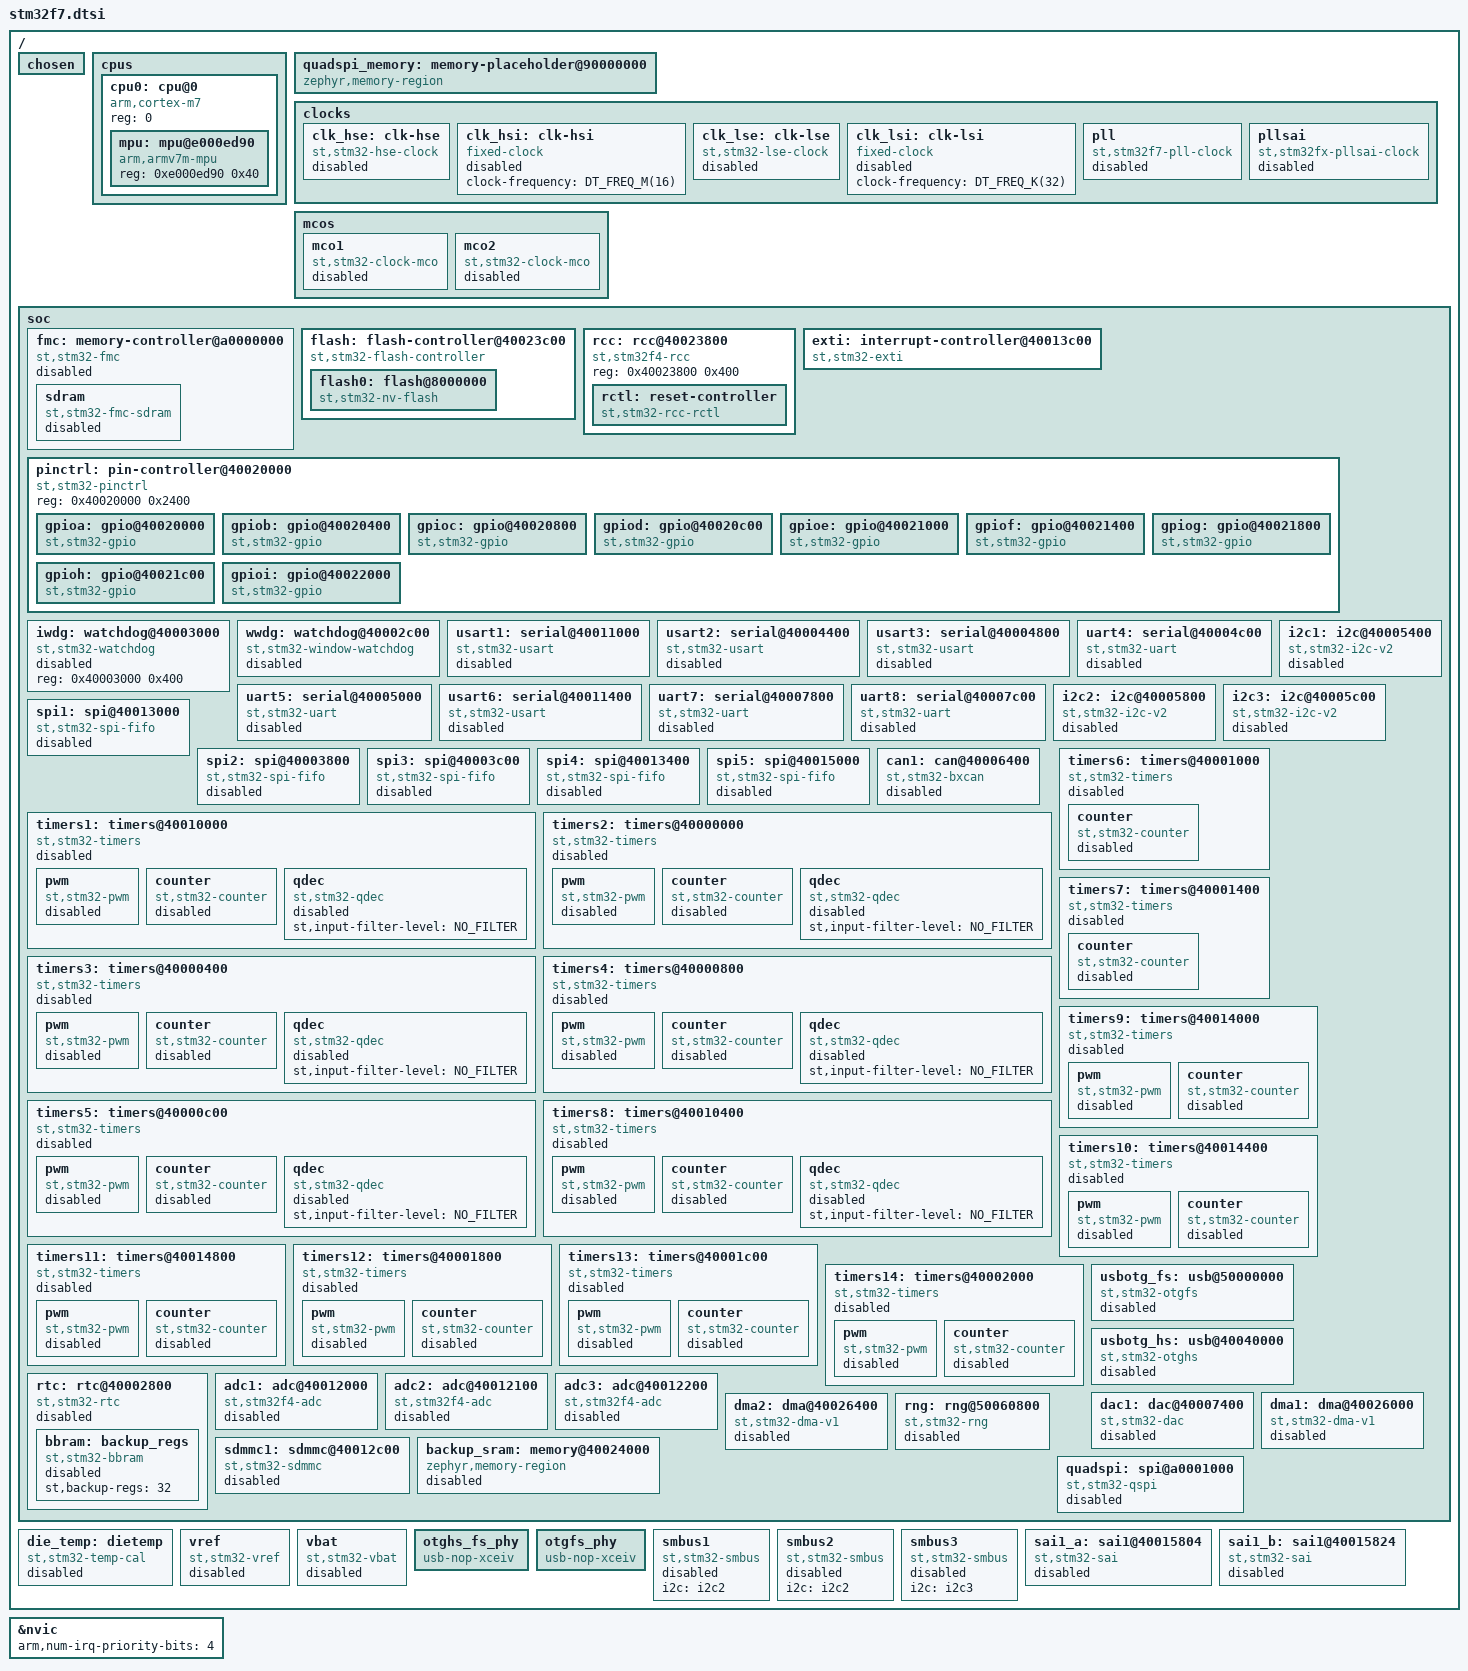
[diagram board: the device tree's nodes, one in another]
/*
 * Copyright (c) 2018 Yurii Hamann
 * Copyright (c) 2019 Centaur Analytics, Inc
 * Copyright (c) 2024 STMicroelectronics
 * Copyright (c) 2025 Mario Paja
 *
 * SPDX-License-Identifier: Apache-2.0
 */

#include <arm/armv7-m.dtsi>
#include <zephyr/dt-bindings/clock/stm32f7_clock.h>
#include <zephyr/dt-bindings/i2c/i2c.h>
#include <zephyr/dt-bindings/gpio/gpio.h>
#include <zephyr/dt-bindings/pwm/pwm.h>
#include <zephyr/dt-bindings/pwm/stm32_pwm.h>
#include <zephyr/dt-bindings/dma/stm32_dma.h>
#include <zephyr/dt-bindings/adc/stm32f4_adc.h>
#include <zephyr/dt-bindings/reset/stm32f2_4_7_reset.h>
#include <zephyr/dt-bindings/adc/adc.h>
#include <zephyr/dt-bindings/memory-controller/stm32-fmc-sdram.h>
#include <zephyr/dt-bindings/sensor/qdec_stm32.h>
#include <zephyr/dt-bindings/memory-attr/memory-attr.h>
#include <zephyr/dt-bindings/memory-attr/memory-attr-arm.h>
#include <freq.h>
#include <mem.h>

/ {
	chosen {
		zephyr,entropy = &rng;
		zephyr,flash-controller = &flash;
	};

	cpus {
		#address-cells = <1>;
		#size-cells = <0>;

		cpu0: cpu@0 {
			device_type = "cpu";
			compatible = "arm,cortex-m7";
			reg = <0>;
			#address-cells = <1>;
			#size-cells = <1>;

			mpu: mpu@e000ed90 {
				compatible = "arm,armv7m-mpu";
				reg = <0xe000ed90 0x40>;
			};
		};
	};

	quadspi_memory: memory-placeholder@90000000 {
		compatible = "zephyr,memory-region", "mmio-sram";
		reg = <0x90000000 DT_SIZE_M(256)>;
		zephyr,memory-region = "QSPI_PLACEHOLDER";
		zephyr,memory-attr = <DT_MEM_ARM(ATTR_MPU_EXTMEM)>;
	};

	clocks {
		clk_hse: clk-hse {
			#clock-cells = <0>;
			compatible = "st,stm32-hse-clock";
			status = "disabled";
		};

		clk_hsi: clk-hsi {
			#clock-cells = <0>;
			compatible = "fixed-clock";
			clock-frequency = <DT_FREQ_M(16)>;
			status = "disabled";
		};

		clk_lse: clk-lse {
			#clock-cells = <0>;
			compatible = "st,stm32-lse-clock";
			clock-frequency = <32768>;
			driving-capability = <0>;
			status = "disabled";
		};

		clk_lsi: clk-lsi {
			#clock-cells = <0>;
			compatible = "fixed-clock";
			clock-frequency = <DT_FREQ_K(32)>;
			status = "disabled";
		};

		pll: pll {
			#clock-cells = <0>;
			compatible = "st,stm32f7-pll-clock";
			status = "disabled";
		};

		pllsai: pllsai {
			compatible = "st,stm32fx-pllsai-clock";
			#clock-cells = <0>;
			status = "disabled";
		};
	};

	mcos {
		mco1: mco1 {
			compatible = "st,stm32-clock-mco";
			status = "disabled";
		};

		mco2: mco2 {
			compatible = "st,stm32-clock-mco";
			status = "disabled";
		};
	};

	soc {
		fmc: memory-controller@a0000000 {
			compatible = "st,stm32-fmc";
			reg = <0xa0000000 0x400>;
			clocks = <&rcc STM32_CLOCK(AHB3, 0)>;
			status = "disabled";

			sdram: sdram {
				compatible = "st,stm32-fmc-sdram";
				#address-cells = <1>;
				#size-cells = <0>;
				status = "disabled";
			};
		};

		flash: flash-controller@40023c00 {
			compatible = "st,stm32-flash-controller", "st,stm32f7-flash-controller";
			reg = <0x40023c00 0x400>;
			interrupts = <4 0>;

			#address-cells = <1>;
			#size-cells = <1>;

			flash0: flash@8000000 {
				compatible = "st,stm32-nv-flash", "soc-nv-flash";

				write-block-size = <1>;
				/* maximum erase time (ms) for a 256K sector */
				max-erase-time = <4000>;
			};
		};

		rcc: rcc@40023800 {
			compatible = "st,stm32f4-rcc";
			#clock-cells = <2>;
			reg = <0x40023800 0x400>;

			rctl: reset-controller {
				compatible = "st,stm32-rcc-rctl";
				#reset-cells = <1>;
			};
		};

		exti: interrupt-controller@40013c00 {
			compatible = "st,stm32-exti";
			interrupt-controller;
			#interrupt-cells = <1>;
			#address-cells = <0>;
			reg = <0x40013c00 0x400>;
			clocks = <&rcc STM32_CLOCK(APB2, 14)>;
			num-lines = <32>;
			interrupts = <6 0>, <7 0>, <8 0>, <9 0>,
				     <10 0>, <23 0>, <40 0>;
			interrupt-names = "line0", "line1", "line2", "line3",
					  "line4", "line5-9", "line10-15";
			line-ranges = <0 1>, <1 1>, <2 1>, <3 1>,
				      <4 1>, <5 5>, <10 6>;
		};

		pinctrl: pin-controller@40020000 {
			compatible = "st,stm32-pinctrl";
			#address-cells = <1>;
			#size-cells = <1>;
			reg = <0x40020000 0x2400>;

			gpioa: gpio@40020000 {
				compatible = "st,stm32-gpio";
				gpio-controller;
				#gpio-cells = <2>;
				reg = <0x40020000 0x400>;
				clocks = <&rcc STM32_CLOCK(AHB1, 0)>;
			};

			gpiob: gpio@40020400 {
				compatible = "st,stm32-gpio";
				gpio-controller;
				#gpio-cells = <2>;
				reg = <0x40020400 0x400>;
				clocks = <&rcc STM32_CLOCK(AHB1, 1)>;
			};

			gpioc: gpio@40020800 {
				compatible = "st,stm32-gpio";
				gpio-controller;
				#gpio-cells = <2>;
				reg = <0x40020800 0x400>;
				clocks = <&rcc STM32_CLOCK(AHB1, 2)>;
			};

			gpiod: gpio@40020c00 {
				compatible = "st,stm32-gpio";
				gpio-controller;
				#gpio-cells = <2>;
				reg = <0x40020c00 0x400>;
				clocks = <&rcc STM32_CLOCK(AHB1, 3)>;
			};

			gpioe: gpio@40021000 {
				compatible = "st,stm32-gpio";
				gpio-controller;
				#gpio-cells = <2>;
				reg = <0x40021000 0x400>;
				clocks = <&rcc STM32_CLOCK(AHB1, 4)>;
			};

			gpiof: gpio@40021400 {
				compatible = "st,stm32-gpio";
				gpio-controller;
				#gpio-cells = <2>;
				reg = <0x40021400 0x400>;
				clocks = <&rcc STM32_CLOCK(AHB1, 5)>;
			};

			gpiog: gpio@40021800 {
				compatible = "st,stm32-gpio";
				gpio-controller;
				#gpio-cells = <2>;
				reg = <0x40021800 0x400>;
				clocks = <&rcc STM32_CLOCK(AHB1, 6)>;
			};

			gpioh: gpio@40021c00 {
				compatible = "st,stm32-gpio";
				gpio-controller;
				#gpio-cells = <2>;
				reg = <0x40021c00 0x400>;
				clocks = <&rcc STM32_CLOCK(AHB1, 7)>;
			};

			gpioi: gpio@40022000 {
				compatible = "st,stm32-gpio";
				gpio-controller;
				#gpio-cells = <2>;
				reg = <0x40022000 0x400>;
				clocks = <&rcc STM32_CLOCK(AHB1, 8)>;
			};
		};

		iwdg: watchdog@40003000 {
			compatible = "st,stm32-watchdog";
			reg = <0x40003000 0x400>;
			status = "disabled";
		};

		wwdg: watchdog@40002c00 {
			compatible = "st,stm32-window-watchdog";
			reg = <0x40002c00 0x400>;
			clocks = <&rcc STM32_CLOCK(APB1, 11)>;
			interrupts = <0 7>;
			status = "disabled";
		};

		usart1: serial@40011000 {
			compatible = "st,stm32-usart", "st,stm32-uart";
			reg = <0x40011000 0x400>;
			clocks = <&rcc STM32_CLOCK(APB2, 4)>;
			resets = <&rctl STM32_RESET(APB2, 4)>;
			interrupts = <37 0>;
			status = "disabled";
		};

		usart2: serial@40004400 {
			compatible = "st,stm32-usart", "st,stm32-uart";
			reg = <0x40004400 0x400>;
			clocks = <&rcc STM32_CLOCK(APB1, 17)>;
			resets = <&rctl STM32_RESET(APB1, 17)>;
			interrupts = <38 0>;
			status = "disabled";
		};

		usart3: serial@40004800 {
			compatible = "st,stm32-usart", "st,stm32-uart";
			reg = <0x40004800 0x400>;
			clocks = <&rcc STM32_CLOCK(APB1, 18)>;
			resets = <&rctl STM32_RESET(APB1, 18)>;
			interrupts = <39 0>;
			status = "disabled";
		};

		uart4: serial@40004c00 {
			compatible = "st,stm32-uart";
			reg = <0x40004c00 0x400>;
			clocks = <&rcc STM32_CLOCK(APB1, 19)>;
			resets = <&rctl STM32_RESET(APB1, 19)>;
			interrupts = <52 0>;
			status = "disabled";
		};

		uart5: serial@40005000 {
			compatible = "st,stm32-uart";
			reg = <0x40005000 0x400>;
			clocks = <&rcc STM32_CLOCK(APB1, 20)>;
			resets = <&rctl STM32_RESET(APB1, 20)>;
			interrupts = <53 0>;
			status = "disabled";
		};

		usart6: serial@40011400 {
			compatible = "st,stm32-usart", "st,stm32-uart";
			reg = <0x40011400 0x400>;
			clocks = <&rcc STM32_CLOCK(APB2, 5)>;
			resets = <&rctl STM32_RESET(APB2, 5)>;
			interrupts = <71 0>;
			status = "disabled";
		};

		uart7: serial@40007800 {
			compatible = "st,stm32-uart";
			reg = <0x40007800 0x400>;
			clocks = <&rcc STM32_CLOCK(APB1, 30)>;
			resets = <&rctl STM32_RESET(APB1, 30)>;
			interrupts = <82 0>;
			status = "disabled";
		};

		uart8: serial@40007c00 {
			compatible = "st,stm32-uart";
			reg = <0x40007c00 0x400>;
			clocks = <&rcc STM32_CLOCK(APB1, 31)>;
			resets = <&rctl STM32_RESET(APB1, 31)>;
			interrupts = <83 0>;
			status = "disabled";
		};

		i2c1: i2c@40005400 {
			compatible = "st,stm32-i2c-v2";
			clock-frequency = <I2C_BITRATE_STANDARD>;
			#address-cells = <1>;
			#size-cells = <0>;
			reg = <0x40005400 0x400>;
			clocks = <&rcc STM32_CLOCK(APB1, 21)>;
			interrupts = <31 0>, <32 0>;
			interrupt-names = "event", "error";
			status = "disabled";
		};

		i2c2: i2c@40005800 {
			compatible = "st,stm32-i2c-v2";
			clock-frequency = <I2C_BITRATE_STANDARD>;
			#address-cells = <1>;
			#size-cells = <0>;
			reg = <0x40005800 0x400>;
			clocks = <&rcc STM32_CLOCK(APB1, 22)>;
			interrupts = <33 0>, <34 0>;
			interrupt-names = "event", "error";
			status = "disabled";
		};

		i2c3: i2c@40005c00 {
			compatible = "st,stm32-i2c-v2";
			clock-frequency = <I2C_BITRATE_STANDARD>;
			#address-cells = <1>;
			#size-cells = <0>;
			reg = <0x40005c00 0x400>;
			clocks = <&rcc STM32_CLOCK(APB1, 23)>;
			interrupts = <72 0>, <73 0>;
			interrupt-names = "event", "error";
			status = "disabled";
		};

		spi1: spi@40013000 {
			compatible = "st,stm32-spi-fifo", "st,stm32-spi";
			#address-cells = <1>;
			#size-cells = <0>;
			reg = <0x40013000 0x400>;
			clocks = <&rcc STM32_CLOCK(APB2, 12)>;
			interrupts = <35 5>;
			status = "disabled";
		};

		spi2: spi@40003800 {
			compatible = "st,stm32-spi-fifo", "st,stm32-spi";
			#address-cells = <1>;
			#size-cells = <0>;
			reg = <0x40003800 0x400>;
			clocks = <&rcc STM32_CLOCK(APB1, 14)>;
			interrupts = <36 5>;
			status = "disabled";
		};

		spi3: spi@40003c00 {
			compatible = "st,stm32-spi-fifo", "st,stm32-spi";
			#address-cells = <1>;
			#size-cells = <0>;
			reg = <0x40003c00 0x400>;
			clocks = <&rcc STM32_CLOCK(APB1, 15)>;
			interrupts = <51 5>;
			status = "disabled";
		};

		spi4: spi@40013400 {
			compatible = "st,stm32-spi-fifo", "st,stm32-spi";
			#address-cells = <1>;
			#size-cells = <0>;
			reg = <0x40013400 0x400>;
			clocks = <&rcc STM32_CLOCK(APB2, 13)>;
			interrupts = <84 5>;
			status = "disabled";
		};

		spi5: spi@40015000 {
			compatible = "st,stm32-spi-fifo", "st,stm32-spi";
			#address-cells = <1>;
			#size-cells = <0>;
			reg = <0x40015000 0x400>;
			clocks = <&rcc STM32_CLOCK(APB2, 20)>;
			interrupts = <85 5>;
			status = "disabled";
		};

		can1: can@40006400 {
			compatible = "st,stm32-bxcan";
			reg = <0x40006400 0x400>;
			interrupts = <19 0>, <20 0>, <21 0>, <22 0>;
			interrupt-names = "TX", "RX0", "RX1", "SCE";
			clocks = <&rcc STM32_CLOCK(APB1, 25)>;
			status = "disabled";
		};

		timers1: timers@40010000 {
			compatible = "st,stm32-timers";
			reg = <0x40010000 0x400>;
			clocks = <&rcc STM32_CLOCK(APB2, 0)>,
				 <&rcc STM32_SRC_TIMPCLK2 NO_SEL>;
			resets = <&rctl STM32_RESET(APB2, 0)>;
			interrupts = <24 0>, <25 0>, <26 0>, <27 0>;
			interrupt-names = "brk", "up", "trgcom", "cc";
			st,prescaler = <0>;
			status = "disabled";

			pwm {
				compatible = "st,stm32-pwm";
				status = "disabled";
				#pwm-cells = <3>;
			};

			counter {
				compatible = "st,stm32-counter";
				status = "disabled";
			};

			qdec {
				compatible = "st,stm32-qdec";
				st,input-filter-level = <NO_FILTER>;
				status = "disabled";
			};
		};

		timers2: timers@40000000 {
			compatible = "st,stm32-timers";
			reg = <0x40000000 0x400>;
			clocks = <&rcc STM32_CLOCK(APB1, 0)>,
				 <&rcc STM32_SRC_TIMPCLK1 NO_SEL>;
			resets = <&rctl STM32_RESET(APB1, 0)>;
			interrupts = <28 0>;
			interrupt-names = "global";
			st,prescaler = <0>;
			status = "disabled";

			pwm {
				compatible = "st,stm32-pwm";
				status = "disabled";
				#pwm-cells = <3>;
			};

			counter {
				compatible = "st,stm32-counter";
				status = "disabled";
			};

			qdec {
				compatible = "st,stm32-qdec";
				st,input-filter-level = <NO_FILTER>;
				status = "disabled";
			};
		};

		timers3: timers@40000400 {
			compatible = "st,stm32-timers";
			reg = <0x40000400 0x400>;
			clocks = <&rcc STM32_CLOCK(APB1, 1)>,
				 <&rcc STM32_SRC_TIMPCLK1 NO_SEL>;
			resets = <&rctl STM32_RESET(APB1, 1)>;
			interrupts = <29 0>;
			interrupt-names = "global";
			st,prescaler = <0>;
			status = "disabled";

			pwm {
				compatible = "st,stm32-pwm";
				status = "disabled";
				#pwm-cells = <3>;
			};

			counter {
				compatible = "st,stm32-counter";
				status = "disabled";
			};

			qdec {
				compatible = "st,stm32-qdec";
				st,input-filter-level = <NO_FILTER>;
				status = "disabled";
			};
		};

		timers4: timers@40000800 {
			compatible = "st,stm32-timers";
			reg = <0x40000800 0x400>;
			clocks = <&rcc STM32_CLOCK(APB1, 2)>,
				 <&rcc STM32_SRC_TIMPCLK1 NO_SEL>;
			resets = <&rctl STM32_RESET(APB1, 2)>;
			interrupts = <30 0>;
			interrupt-names = "global";
			st,prescaler = <0>;
			status = "disabled";

			pwm {
				compatible = "st,stm32-pwm";
				status = "disabled";
				#pwm-cells = <3>;
			};

			counter {
				compatible = "st,stm32-counter";
				status = "disabled";
			};

			qdec {
				compatible = "st,stm32-qdec";
				st,input-filter-level = <NO_FILTER>;
				status = "disabled";
			};
		};

		timers5: timers@40000c00 {
			compatible = "st,stm32-timers";
			reg = <0x40000c00 0x400>;
			clocks = <&rcc STM32_CLOCK(APB1, 3)>,
				 <&rcc STM32_SRC_TIMPCLK1 NO_SEL>;
			resets = <&rctl STM32_RESET(APB1, 3)>;
			interrupts = <50 0>;
			interrupt-names = "global";
			st,prescaler = <0>;
			status = "disabled";

			pwm {
				compatible = "st,stm32-pwm";
				status = "disabled";
				#pwm-cells = <3>;
			};

			counter {
				compatible = "st,stm32-counter";
				status = "disabled";
			};

			qdec {
				compatible = "st,stm32-qdec";
				st,input-filter-level = <NO_FILTER>;
				status = "disabled";
			};
		};

		timers6: timers@40001000 {
			compatible = "st,stm32-timers";
			reg = <0x40001000 0x400>;
			clocks = <&rcc STM32_CLOCK(APB1, 4)>,
				 <&rcc STM32_SRC_TIMPCLK1 NO_SEL>;
			resets = <&rctl STM32_RESET(APB1, 4)>;
			interrupts = <54 0>;
			interrupt-names = "global";
			st,prescaler = <0>;
			status = "disabled";

			counter {
				compatible = "st,stm32-counter";
				status = "disabled";
			};
		};

		timers7: timers@40001400 {
			compatible = "st,stm32-timers";
			reg = <0x40001400 0x400>;
			clocks = <&rcc STM32_CLOCK(APB1, 5)>,
				 <&rcc STM32_SRC_TIMPCLK1 NO_SEL>;
			resets = <&rctl STM32_RESET(APB1, 5)>;
			interrupts = <55 0>;
			interrupt-names = "global";
			st,prescaler = <0>;
			status = "disabled";

			counter {
				compatible = "st,stm32-counter";
				status = "disabled";
			};
		};

		timers8: timers@40010400 {
			compatible = "st,stm32-timers";
			reg = <0x40010400 0x400>;
			clocks = <&rcc STM32_CLOCK(APB2, 1)>,
				 <&rcc STM32_SRC_TIMPCLK2 NO_SEL>;
			resets = <&rctl STM32_RESET(APB2, 1)>;
			interrupts = <43 0>, <44 0>, <45 0>, <46 0>;
			interrupt-names = "brk", "up", "trgcom", "cc";
			st,prescaler = <0>;
			status = "disabled";

			pwm {
				compatible = "st,stm32-pwm";
				status = "disabled";
				#pwm-cells = <3>;
			};

			counter {
				compatible = "st,stm32-counter";
				status = "disabled";
			};

			qdec {
				compatible = "st,stm32-qdec";
				st,input-filter-level = <NO_FILTER>;
				status = "disabled";
			};
		};

		timers9: timers@40014000 {
			compatible = "st,stm32-timers";
			reg = <0x40014000 0x400>;
			clocks = <&rcc STM32_CLOCK(APB2, 16)>,
				 <&rcc STM32_SRC_TIMPCLK2 NO_SEL>;
			resets = <&rctl STM32_RESET(APB2, 16)>;
			interrupts = <24 0>;
			interrupt-names = "global";
			st,prescaler = <0>;
			status = "disabled";

			pwm {
				compatible = "st,stm32-pwm";
				status = "disabled";
				#pwm-cells = <3>;
			};

			counter {
				compatible = "st,stm32-counter";
				status = "disabled";
			};
		};

		timers10: timers@40014400 {
			compatible = "st,stm32-timers";
			reg = <0x40014400 0x400>;
			clocks = <&rcc STM32_CLOCK(APB2, 17)>,
				 <&rcc STM32_SRC_TIMPCLK2 NO_SEL>;
			resets = <&rctl STM32_RESET(APB2, 17)>;
			interrupts = <25 0>;
			interrupt-names = "global";
			st,prescaler = <0>;
			status = "disabled";

			pwm {
				compatible = "st,stm32-pwm";
				status = "disabled";
				#pwm-cells = <3>;
			};

			counter {
				compatible = "st,stm32-counter";
				status = "disabled";
			};
		};

		timers11: timers@40014800 {
			compatible = "st,stm32-timers";
			reg = <0x40014800 0x400>;
			clocks = <&rcc STM32_CLOCK(APB2, 18)>,
				 <&rcc STM32_SRC_TIMPCLK2 NO_SEL>;
			resets = <&rctl STM32_RESET(APB2, 18)>;
			interrupts = <26 0>;
			interrupt-names = "global";
			st,prescaler = <0>;
			status = "disabled";

			pwm {
				compatible = "st,stm32-pwm";
				status = "disabled";
				#pwm-cells = <3>;
			};

			counter {
				compatible = "st,stm32-counter";
				status = "disabled";
			};
		};

		timers12: timers@40001800 {
			compatible = "st,stm32-timers";
			reg = <0x40001800 0x400>;
			clocks = <&rcc STM32_CLOCK(APB1, 6)>,
				 <&rcc STM32_SRC_TIMPCLK1 NO_SEL>;
			resets = <&rctl STM32_RESET(APB1, 6)>;
			interrupts = <43 0>;
			interrupt-names = "global";
			st,prescaler = <0>;
			status = "disabled";

			pwm {
				compatible = "st,stm32-pwm";
				status = "disabled";
				#pwm-cells = <3>;
			};

			counter {
				compatible = "st,stm32-counter";
				status = "disabled";
			};
		};

		timers13: timers@40001c00 {
			compatible = "st,stm32-timers";
			reg = <0x40001c00 0x400>;
			clocks = <&rcc STM32_CLOCK(APB1, 7)>,
				 <&rcc STM32_SRC_TIMPCLK1 NO_SEL>;
			resets = <&rctl STM32_RESET(APB1, 7)>;
			interrupts = <44 0>;
			interrupt-names = "global";
			st,prescaler = <0>;
			status = "disabled";

			pwm {
				compatible = "st,stm32-pwm";
				status = "disabled";
				#pwm-cells = <3>;
			};

			counter {
				compatible = "st,stm32-counter";
				status = "disabled";
			};
		};

		timers14: timers@40002000 {
			compatible = "st,stm32-timers";
			reg = <0x40002000 0x400>;
			clocks = <&rcc STM32_CLOCK(APB1, 8)>,
				 <&rcc STM32_SRC_TIMPCLK1 NO_SEL>;
			resets = <&rctl STM32_RESET(APB1, 8)>;
			interrupts = <45 0>;
			interrupt-names = "global";
			st,prescaler = <0>;
			status = "disabled";

			pwm {
				compatible = "st,stm32-pwm";
				status = "disabled";
				#pwm-cells = <3>;
			};

			counter {
				compatible = "st,stm32-counter";
				status = "disabled";
			};
		};

		usbotg_fs: usb@50000000 {
			compatible = "st,stm32-otgfs";
			reg = <0x50000000 0x40000>;
			interrupts = <67 0>;
			interrupt-names = "otgfs";
			num-bidir-endpoints = <6>;
			ram-size = <1280>;
			maximum-speed = "full-speed";
			phys = <&otgfs_phy>;
			clocks = <&rcc STM32_CLOCK(AHB2, 7)>,
				 <&rcc STM32_SRC_PLL_Q CK48M_SEL(0)>;
			status = "disabled";
		};

		usbotg_hs: usb@40040000 {
			compatible = "st,stm32-otghs";
			reg = <0x40040000 0x40000>;
			interrupts = <77 0>, <74 0>, <75 0>;
			interrupt-names = "otghs", "ep1_out", "ep1_in";
			num-bidir-endpoints = <9>;
			ram-size = <4096>;
			maximum-speed = "full-speed";
			clocks = <&rcc STM32_CLOCK(AHB1, 29)>,
				 <&rcc STM32_SRC_PLL_Q CK48M_SEL(0)>;
			phys = <&otghs_fs_phy>;
			status = "disabled";
		};

		rtc: rtc@40002800 {
			compatible = "st,stm32-rtc";
			reg = <0x40002800 0x300>;
			interrupts = <41 0>;
			clocks = <&rcc STM32_CLOCK(APB1, 28)>;
			prescaler = <32768>;
			alarms-count = <2>;
			alrm-exti-line = <17>;
			status = "disabled";

			bbram: backup_regs {
				compatible = "st,stm32-bbram";
				st,backup-regs = <32>;
				status = "disabled";
			};
		};

		adc1: adc@40012000 {
			compatible = "st,stm32f4-adc", "st,stm32-adc";
			reg = <0x40012000 0x50>;
			clocks = <&rcc STM32_CLOCK(APB2, 8)>;
			clock-names = "adcx";
			interrupts = <18 0>;
			#io-channel-cells = <1>;
			resolutions = <STM32_ADC_RES(12, 0x00)
				       STM32_ADC_RES(10, 0x01)
				       STM32_ADC_RES(8, 0x02)
				       STM32_ADC_RES(6, 0x03)>;
			sampling-times = <3 15 28 56 84 112 144 480>;
			st,adc-clock-source = "SYNC";
			st,adc-sequencer = "programmable";
			st,adc-oversampler = "none";
			st,adc-internal-regulator = "none";
			status = "disabled";
		};

		adc2: adc@40012100 {
			compatible = "st,stm32f4-adc", "st,stm32-adc";
			reg = <0x40012100 0x50>;
			clocks = <&rcc STM32_CLOCK(APB2, 9)>;
			clock-names = "adcx";
			interrupts = <18 0>;
			#io-channel-cells = <1>;
			resolutions = <STM32_ADC_RES(12, 0x00)
				       STM32_ADC_RES(10, 0x01)
				       STM32_ADC_RES(8, 0x02)
				       STM32_ADC_RES(6, 0x03)>;
			sampling-times = <3 15 28 56 84 112 144 480>;
			st,adc-clock-source = "SYNC";
			st,adc-sequencer = "programmable";
			st,adc-oversampler = "none";
			st,adc-internal-regulator = "none";
			status = "disabled";
		};

		adc3: adc@40012200 {
			compatible = "st,stm32f4-adc", "st,stm32-adc";
			reg = <0x40012200 0x50>;
			clocks = <&rcc STM32_CLOCK(APB2, 10)>;
			clock-names = "adcx";
			interrupts = <18 0>;
			#io-channel-cells = <1>;
			resolutions = <STM32_ADC_RES(12, 0x00)
				       STM32_ADC_RES(10, 0x01)
				       STM32_ADC_RES(8, 0x02)
				       STM32_ADC_RES(6, 0x03)>;
			sampling-times = <3 15 28 56 84 112 144 480>;
			st,adc-clock-source = "SYNC";
			st,adc-sequencer = "programmable";
			st,adc-oversampler = "none";
			st,adc-internal-regulator = "none";
			status = "disabled";
		};

		dac1: dac@40007400 {
			compatible = "st,stm32-dac";
			reg = <0x40007400 0x400>;
			clocks = <&rcc STM32_CLOCK(APB1, 29)>;
			status = "disabled";
			#io-channel-cells = <1>;
		};

		dma1: dma@40026000 {
			compatible = "st,stm32-dma-v1";
			#dma-cells = <4>;
			reg = <0x40026000 0x400>;
			interrupts = <11 0 12 0 13 0 14 0 15 0 16 0 17 0 47 0>;
			clocks = <&rcc STM32_CLOCK(AHB1, 21)>;
			status = "disabled";
		};

		dma2: dma@40026400 {
			compatible = "st,stm32-dma-v1";
			#dma-cells = <4>;
			reg = <0x40026400 0x400>;
			interrupts = <56 0 57 0 58 0 59 0 60 0 68 0 69 0 70 0>;
			clocks = <&rcc STM32_CLOCK(AHB1, 22)>;
			st,mem2mem;
			status = "disabled";
		};

		rng: rng@50060800 {
			compatible = "st,stm32-rng";
			reg = <0x50060800 0x400>;
			interrupts = <80 0>;
			clocks = <&rcc STM32_CLOCK(AHB2, 6)>,
				 <&rcc STM32_SRC_PLL_Q CK48M_SEL(0)>;
			status = "disabled";
		};

		sdmmc1: sdmmc@40012c00 {
			compatible = "st,stm32-sdmmc";
			reg = <0x40012c00 0x400>;
			clocks = <&rcc STM32_CLOCK(APB2, 11)>,
				 <&rcc STM32_SRC_PLL_Q SDMMC1_SEL(0)>;
			resets = <&rctl STM32_RESET(APB2, 11)>;
			interrupts = <49 0>;
			status = "disabled";
		};

		backup_sram: memory@40024000 {
			compatible = "zephyr,memory-region", "st,stm32-backup-sram";
			reg = <0x40024000 DT_SIZE_K(4)>;
			clocks = <&rcc STM32_CLOCK(AHB1, 18)>;
			zephyr,memory-region = "BACKUP_SRAM";
			status = "disabled";
		};

		quadspi: spi@a0001000 {
			compatible = "st,stm32-qspi";
			#address-cells = <1>;
			#size-cells = <0>;
			reg = <0xa0001000 0x1000>, <0x90000000 DT_SIZE_M(256)>;
			interrupts = <92 0>;
			clocks = <&rcc STM32_CLOCK(AHB3, 1)>;
			status = "disabled";
		};
	};

	die_temp: dietemp {
		compatible = "st,stm32-temp-cal";
		ts-cal1-addr = <0x1ff0f44c>;
		ts-cal2-addr = <0x1ff0f44e>;
		ts-cal1-temp = <30>;
		ts-cal2-temp = <110>;
		ts-cal-vrefanalog = <3300>;
		io-channels = <&adc1 18>;
		status = "disabled";
	};

	vref: vref {
		compatible = "st,stm32-vref";
		vrefint-cal-addr = <0x1ff0f44a>;
		vrefint-cal-mv = <3300>;
		io-channels = <&adc1 17>;
		status = "disabled";
	};

	vbat: vbat {
		compatible = "st,stm32-vbat";
		ratio = <4>;
		io-channels = <&adc1 18>;
		status = "disabled";
	};

	otghs_fs_phy: otghs_fs_phy {
		compatible = "usb-nop-xceiv";
		#phy-cells = <0>;
	};

	otgfs_phy: otgfs_phy {
		compatible = "usb-nop-xceiv";
		#phy-cells = <0>;
	};

	smbus1: smbus1 {
		compatible = "st,stm32-smbus";
		#address-cells = <1>;
		#size-cells = <0>;
		i2c = <&i2c2>;
		status = "disabled";
	};

	smbus2: smbus2 {
		compatible = "st,stm32-smbus";
		#address-cells = <1>;
		#size-cells = <0>;
		i2c = <&i2c2>;
		status = "disabled";
	};

	smbus3: smbus3 {
		compatible = "st,stm32-smbus";
		#address-cells = <1>;
		#size-cells = <0>;
		i2c = <&i2c3>;
		status = "disabled";
	};

	sai1_a: sai1@40015804 {
		compatible = "st,stm32-sai";
		#address-cells = <1>;
		#size-cells = <0>;
		reg = <0x40015804 0x20>;
		clocks = <&rcc STM32_CLOCK(APB2, 22)>;
		dmas = <&dma2 1 0 (STM32_DMA_MODE_NORMAL | STM32_DMA_PRIORITY_HIGH |
			STM32_DMA_16BITS) 0>;
		status = "disabled";
	};

	sai1_b: sai1@40015824 {
		compatible = "st,stm32-sai";
		#address-cells = <1>;
		#size-cells = <0>;
		reg = <0x40015824 0x20>;
		clocks = <&rcc STM32_CLOCK(APB2, 22)>;
		dmas = <&dma2 5 0 (STM32_DMA_MODE_NORMAL | STM32_DMA_PRIORITY_HIGH |
			STM32_DMA_16BITS) 0>;
		status = "disabled";
	};
};

&nvic {
	arm,num-irq-priority-bits = <4>;
};
